# ESP32S31_RADIO register map
Vendor: Espressif; Series: ESP32-S31; File version: 3.52
Registers are 32-bit, read-write, no defined reset value unless marked. A register's access mark holds for its fields unless they carry their own. Offsets are from the block's base; [hi:lo] are bit positions.

## WIFI_MAC_INTERRUPT — Wi-Fi MAC interrupt mask, masked status and write-to-clear aperture. The two complete hal_mac leaves independently prove the status and clear addresses. The recovered common FIQ and cold initializer prove the event-bit mapping and mask transaction used by the open ISR.
Base 0x20104C40
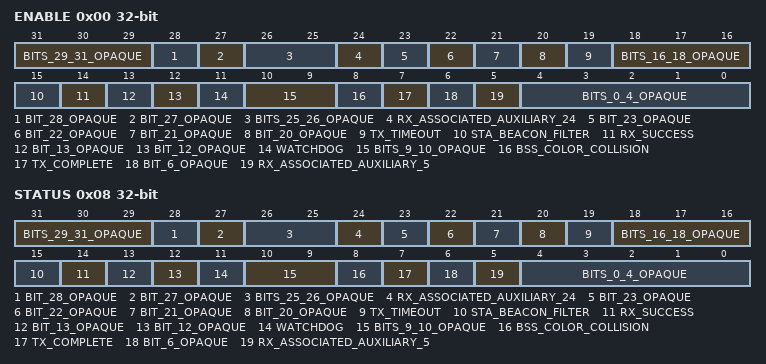
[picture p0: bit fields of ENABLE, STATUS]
0x00 ENABLE — Project-assigned name. Complete hal_init first publishes 0x19a879e0 here before its remaining tail. Complete hal_enable_mac independently publishes its argument after clearing the shared MAC disable gates. The common FIQ samples it with each interrupt status snapshot.
  [31:29] BITS_29_31_OPAQUE — Opaque: meaning not established. Interrupt-enable bits whose event identities remain unknown.
  [28] BIT_28_OPAQUE — Opaque: meaning not established. Unknown event enabled by the complete cold receive mask.
  [27] BIT_27_OPAQUE — Opaque: meaning not established. Unknown event enabled by the complete cold receive mask.
  [26:25] BITS_25_26_OPAQUE — Opaque: meaning not established. Interrupt-enable bits whose event identities remain unknown.
  [24] RX_ASSOCIATED_AUXILIARY_24 — Project-assigned name. Enable for the status bit observed together with RX_SUCCESS during sustained receive traffic.
  [23] BIT_23_OPAQUE — Opaque: meaning not established. Unknown event enabled by the complete cold receive mask.
  [22] BIT_22_OPAQUE — Opaque: meaning not established. Interrupt-enable bit whose event identity remains unknown.
  [21] BIT_21_OPAQUE — Opaque: meaning not established. Unknown event enabled by the complete cold receive mask.
  [20] BIT_20_OPAQUE — Opaque: meaning not established. Interrupt-enable bit whose event identity remains unknown.
  [19] TX_TIMEOUT — Project-assigned name. Enable for the hardware TX queue timeout/abort event.
  [18:16] BITS_16_18_OPAQUE — Opaque: meaning not established. Interrupt-enable bits whose event identities remain unknown.
  [15] STA_BEACON_FILTER — Project-assigned name. Enable for the station beacon-filter event; the complete disable leaf clears this bit after disabling the filter hardware.
  [14] RX_SUCCESS — Project-assigned name. Enable for successful receive completion.
  [13] BIT_13_OPAQUE — Opaque: meaning not established. Unknown event enabled by the complete cold receive mask.
  [12] BIT_12_OPAQUE — Opaque: meaning not established. Unknown event enabled by the complete cold receive mask.
  [11] WATCHDOG — Project-assigned name. Enable for the MAC watchdog event.
  [10:9] BITS_9_10_OPAQUE — Opaque: meaning not established. Interrupt-enable bits whose event identities remain unknown.
  [8] BSS_COLOR_COLLISION — Project-assigned name. Enable for the HE BSS-color collision event.
  [7] TX_COMPLETE — Project-assigned name. Enable for the TX-complete event.
  [6] BIT_6_OPAQUE — Opaque: meaning not established. Unknown event enabled by the complete cold receive mask.
  [5] RX_ASSOCIATED_AUXILIARY_5 — Project-assigned name. Enable for the status bit observed together with RX_SUCCESS during sustained receive traffic.
  [4:0] BITS_0_4_OPAQUE — Opaque: meaning not established. Interrupt-enable bits whose event identities remain unknown.
0x04 RAW — Project-assigned name. Unmasked WDEV interrupt snapshot read by print_isr_regs. Complete hal_disable_mac writes zero after masking ENABLE.
  [31:0] EVENTS — Project-assigned name.
0x08 STATUS ro — Project-assigned name. Masked MAC event snapshot read by the complete hal_mac_interrupt_get_event leaf. Its bit geometry matches the complete ENABLE event bank; only independently recovered event identities are named semantically.
  [31:29] BITS_29_31_OPAQUE — Opaque: meaning not established. Masked event bits whose identities remain unknown.
  [28] BIT_28_OPAQUE — Opaque: meaning not established. Masked event bit enabled by the complete cold receive mask; its event identity remains unknown.
  [27] BIT_27_OPAQUE — Opaque: meaning not established. Masked event bit enabled by the complete cold receive mask; its event identity remains unknown.
  [26:25] BITS_25_26_OPAQUE — Opaque: meaning not established. Masked event bits whose identities remain unknown.
  [24] RX_ASSOCIATED_AUXILIARY_24 — Project-assigned name. Enabled by the cold MAC mask 0x19a879e0 and observed asserted with RX_SUCCESS throughout sustained HE20 receive traffic. Complete libpp[wdev.o]::wDev_ProcessFiq acknowledges this bit as part of the full STATUS image but does not dispatch independent work for it. Its hardware meaning and independent transition rules remain unknown; software must not treat it as RX ownership or work multiplicity.
  [23] BIT_23_OPAQUE — Opaque: meaning not established. Masked event bit enabled by the complete cold receive mask; its event identity remains unknown.
  [22] BIT_22_OPAQUE — Opaque: meaning not established. Masked event bit whose identity remains unknown.
  [21] BIT_21_OPAQUE — Opaque: meaning not established. Masked event bit enabled by the complete cold receive mask; its event identity remains unknown.
  [20] BIT_20_OPAQUE — Opaque: meaning not established. Masked event bit whose identity remains unknown.
  [19] TX_TIMEOUT — Project-assigned name. Hardware TX queue timeout/abort event.
  [18:16] BITS_16_18_OPAQUE — Opaque: meaning not established. Masked event bits whose identities remain unknown.
  [15] STA_BEACON_FILTER — Project-assigned name. Masked station beacon-filter event. The paired ENABLE field identity is recovered from the complete disable leaf; no task-side dispatch is claimed here.
  [14] RX_SUCCESS — Project-assigned name. Successfully received frame is ready for the RX completion path.
  [13] BIT_13_OPAQUE — Opaque: meaning not established. Masked event bit enabled by the complete cold receive mask; its event identity remains unknown.
  [12] BIT_12_OPAQUE — Opaque: meaning not established. Masked event bit enabled by the complete cold receive mask; its event identity remains unknown.
  [11] WATCHDOG — Project-assigned name. MAC watchdog event cleared by the complete dedicated leaf.
  [10:9] BITS_9_10_OPAQUE — Opaque: meaning not established. Masked event bits whose identities remain unknown.
  [8] BSS_COLOR_COLLISION — Project-assigned name. HE BSS-color collision event.
  [7] TX_COMPLETE — Project-assigned name. At least one hardware TX queue completed.
  [6] BIT_6_OPAQUE — Opaque: meaning not established. Masked event bit enabled by the complete cold receive mask; its event identity remains unknown.
  [5] RX_ASSOCIATED_AUXILIARY_5 — Project-assigned name. Enabled by the cold MAC mask 0x19a879e0 and observed asserted with RX_SUCCESS throughout sustained HE20 receive traffic. Complete libpp[wdev.o]::wDev_ProcessFiq acknowledges this bit as part of the full STATUS image but does not dispatch independent work for it. Its hardware meaning and independent transition rules remain unknown; software must not treat it as RX ownership or work multiplicity.
  [4:0] BITS_0_4_OPAQUE — Opaque: meaning not established. Masked event bits whose identities remain unknown.
0x0C CLEAR wo write-1-clears — Project-assigned name. Full event snapshot written by the complete clear leaf to acknowledge pending MAC events.
  [31:0] EVENTS — Project-assigned name. Ones acknowledge the corresponding event bits.
